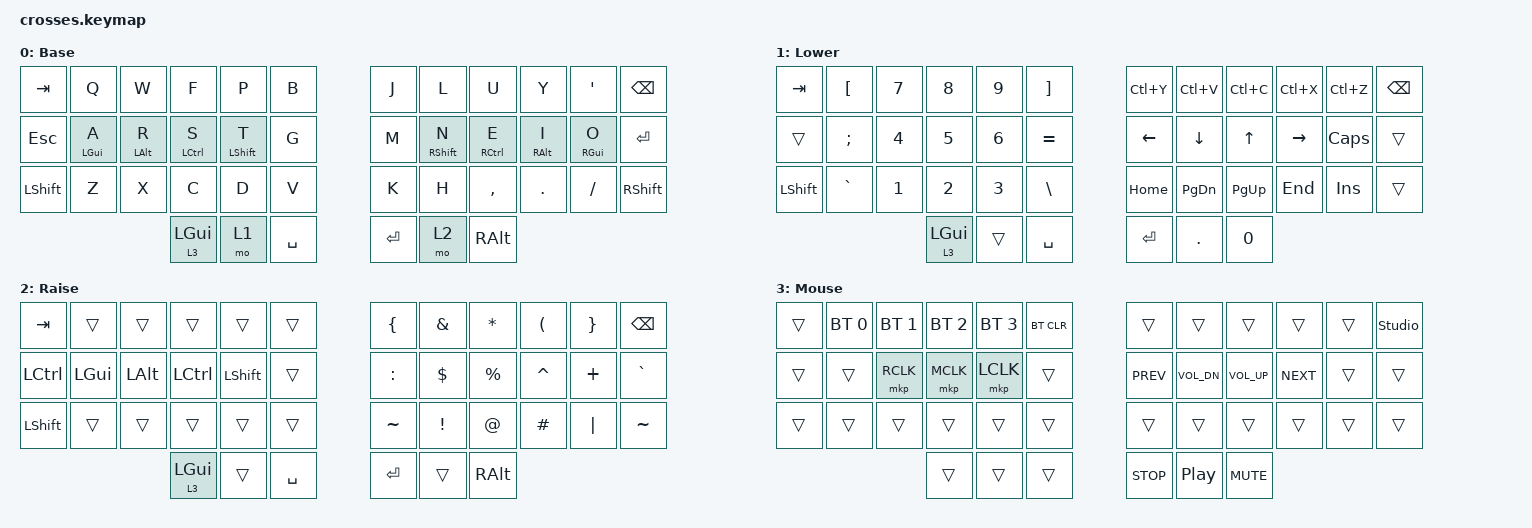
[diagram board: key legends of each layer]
#include <behaviors.dtsi>
#include <dt-bindings/zmk/bt.h>
#include <dt-bindings/zmk/keys.h>
#include <dt-bindings/zmk/pointing.h>

/ {
    chosen { zmk,physical-layout = &gggw_crosses_42_layout; };

    behaviors {
        hm: homerow_mod {
            compatible = "zmk,behavior-hold-tap";
            #binding-cells = <2>;
            tapping_term_ms = <280>;
            quick_tap_ms = <175>;
            flavor = "balanced";
            bindings = <&kp>, <&kp>;
        };
    };

    keymap {
        compatible = "zmk,keymap";

        default_layer {
            display-name = "Base";
            bindings = 
                &kp TAB    &kp Q       &kp W       &kp F        &kp P        &kp B       &kp J    &kp L        &kp U        &kp Y       &kp SQT     &kp BSPC
                &kp ESC    &hm LGUI A  &hm LALT R  &hm LCTRL S  &hm LSHFT T  &kp G       &kp M    &hm RSHFT N  &hm RCTRL E  &hm RALT I  &hm RGUI O  &kp RET
                &kp LSHFT  &kp Z       &kp X       &kp C        &kp D        &kp V       &kp K    &kp H        &kp COMMA    &kp DOT     &kp FSLH    &kp RSHFT
                                                    &lt 3 LGUI   &mo 1        &kp SPACE   &kp RET  &mo 2        &kp RALT
            >;
        };

        lower_layer {
            display-name = "Lower";
            bindings = 
                &kp TAB    &kp LBKT   &kp N7  &kp N8   &kp N9  &kp RBKT     &kp LC(Y)  &kp LC(V)  &kp LC(C)  &kp LC(X)  &kp LC(Z)  &kp BSPC
                &trans     &kp SEMI   &kp N4  &kp N5   &kp N6  &kp EQUAL    &kp LEFT   &kp DOWN   &kp UP     &kp RIGHT  &kp CAPS   &trans
                &kp LSHFT  &kp GRAVE  &kp N1  &kp N2   &kp N3  &kp BSLH     &kp HOME   &kp PG_DN  &kp PG_UP  &kp END    &kp INS    &trans
                                               &lt 3 LGUI  &trans  &kp SPACE    &kp RET    &kp DOT    &kp N0
            >;
        };

        raise_layer {
            display-name = "Raise";
            bindings = 
                &kp TAB    &trans    &trans    &trans     &trans     &trans    &kp LBRC   &kp AMPS   &kp ASTRK  &kp LPAR   &kp RBRC   &kp BSPC
                &kp LCTRL  &kp LGUI  &kp LALT  &kp LCTRL  &kp LSHFT  &trans    &kp COLON  &kp DLLR   &kp PRCNT  &kp CARET  &kp PLUS   &kp GRAVE
                &kp LSHFT  &trans    &trans    &trans     &trans     &trans    &kp TILDE  &kp EXCL   &kp AT     &kp HASH   &kp PIPE   &kp TILDE
                                               &lt 3 LGUI  &trans     &kp SPACE  &kp RET    &trans     &kp RALT
            >;
        };

        mouse_layer {
            display-name = "Mouse";
            bindings = 
                &trans  &bt BT_SEL 0  &bt BT_SEL 1  &bt BT_SEL 2  &bt BT_SEL 3  &bt BT_CLR    &trans      &trans        &trans        &trans      &trans     &studio_unlock
                &trans  &trans        &mkp RCLK     &mkp MCLK     &mkp LCLK     &trans        &kp C_PREV  &kp C_VOL_DN  &kp C_VOL_UP  &kp C_NEXT  &trans     &trans
                &trans  &trans        &trans        &trans        &trans        &trans        &trans      &trans        &trans        &trans      &trans     &trans
                                                    &trans        &trans        &trans        &kp C_STOP  &kp C_PP      &kp C_MUTE
            >;
        };
    };
};
